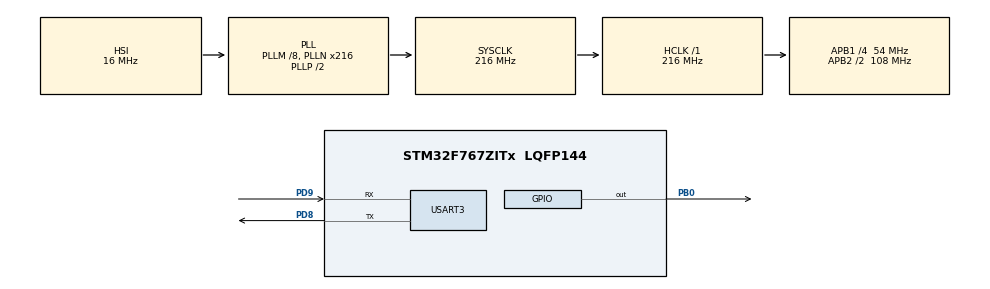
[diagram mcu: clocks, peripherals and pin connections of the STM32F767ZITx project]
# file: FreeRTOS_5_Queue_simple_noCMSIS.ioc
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FREERTOS.INCLUDE_vTaskDelayUntil=1
FREERTOS.Tasks01=normalTask,0,128,start_normalTask,Default,NULL,Dynamic,NULL,NULL
FREERTOS.configUSE_COUNTING_SEMAPHORES=0
FREERTOS.configUSE_NEWLIB_REENTRANT=1
Mcu.Family=STM32F7
Mcu.Name=STM32F767ZITx
Mcu.Package=LQFP144
NVIC.PriorityGroup=NVIC_PRIORITYGROUP_4
NVIC.TIM6_DAC_IRQn=true\:15\:0\:false\:false\:true\:false\:false\:true\:true
NVIC.TimeBase=TIM6_DAC_IRQn
NVIC.TimeBaseIP=TIM6
NVIC.USART3_IRQn=true\:5\:0\:false\:false\:true\:true\:true\:true\:true
PA13.Mode=Serial_Wire
PA13.Signal=SYS_JTMS-SWDIO
PA14.Mode=Serial_Wire
PA14.Signal=SYS_JTCK-SWCLK
PB0.Signal=GPIO_Output
PD8.Mode=Asynchronous
PD8.Signal=USART3_TX
PD9.Mode=Asynchronous
PD9.Signal=USART3_RX
ProjectManager.HeapSize=0x200
ProjectManager.StackSize=0x400
ProjectManager.TargetToolchain=CMake
RCC.AHBFreq_Value=216000000
RCC.APB1CLKDivider=RCC_HCLK_DIV4
RCC.APB1Freq_Value=54000000
RCC.APB1TimFreq_Value=108000000
RCC.APB2CLKDivider=RCC_HCLK_DIV2
RCC.APB2Freq_Value=108000000
RCC.APB2TimFreq_Value=216000000
RCC.CortexFreq_Value=216000000
RCC.HCLKFreq_Value=216000000
RCC.HSE_VALUE=8000000
RCC.HSI_VALUE=16000000
RCC.LSE_VALUE=32768
RCC.PLLM=8
RCC.PLLN=216
RCC.SYSCLKFreq_VALUE=216000000
RCC.SYSCLKSource=RCC_SYSCLKSOURCE_PLLCLK
RCC.USBFreq_Value=216000000
RCC.VCOOutputFreq_Value=432000000
USART3.VirtualMode-Asynchronous=VM_ASYNC
VP_FREERTOS_VS_CMSIS_V1.Mode=CMSIS_V1
VP_SYS_VS_tim6.Mode=TIM6
board=custom

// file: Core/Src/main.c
/* USER CODE BEGIN Header */
/**
  ******************************************************************************
  * @file           : main.c
  * @brief          : Main program body
  ******************************************************************************
  * @author			: Jabed-Akhtar (GitHub)
  * @date			: 11.10.2022
  ******************************************************************************
  * Description:
  * 	- a source within this script: https://youtube.com/playlist?list=PLfIJKC1ud8gj1t2y36sabPT4YcKzmN_5D
  * 	- Related doc/file can be found at location '<project-dir>/zz_docs/FreeRTOS_5_Queue_simple_noCMSIS_161204_Mastering_the_FreeRTOS_Real_Time_Kernel-A_Hands-On_Tutorial_Guide-Page-131.jpg'
  * 	- Task Sender_HPT_Task sends data every 2 sec
  * 	- Task Sender_LPT_Task sends data every 1 sec
  * 	- Task Receiver_Task reads data from Queue every 5 sec
  * 	- Rx_UART write data to front of Queue (when the Queue is full, data
  * 	  won't be written to Queue -> to test, write data in the beginning
  * 	  of programm execution.)
  *
  * @attention
  * Very imp note:
  * 	- comment out #include "cmsis_os.h" , as it is not used
  * 	- comment or remote by-default created task related stuffs
  *
  ******************************************************************************
  */
/* USER CODE END Header */
#include "main.h"
//#include "cmsis_os.h"

/* USER CODE BEGIN Includes */

#include "FreeRTOS.h"
#include "task.h"
#include "timers.h"
#include "queue.h"
#include "semphr.h"
#include "event_groups.h"

#include <stdio.h>
#include "stdlib.h"
#include <string.h>

/* USER CODE END Includes */

UART_HandleTypeDef huart3;

//osThreadId normalTaskHandle;
/* USER CODE BEGIN PV */

// defining Task Handlers
xTaskHandle Sender_HPT_Handler;
xTaskHandle Sender_LPT_Handler;
xTaskHandle Receiver_Handler;

// defining Queue Handlers
xQueueHandle simpleQueue;

uint8_t Rx_data;

/* USER CODE END PV */

void SystemClock_Config(void);
static void MX_GPIO_Init(void);
static void MX_USART3_UART_Init(void);
//void start_normalTask(void const * argument);

/* USER CODE BEGIN PFP */

void Sender_HPT_Task(void *argument); // Sender High Priority task Handler function
void Sender_LPT_Task(void *argument); // Sender Low Priority task Handler function
void Receiver_Task(void *argument); // Receiver task Handler function

/* USER CODE END PFP */

int main(void)
{

  /* MCU Configuration--------------------------------------------------------*/

  /* Reset of all peripherals, Initializes the Flash interface and the Systick. */
  HAL_Init();

  /* Configure the system clock */
  SystemClock_Config();

  /* Initialize all configured peripherals */
  MX_GPIO_Init();
  MX_USART3_UART_Init();
  /* USER CODE BEGIN 2 */

  // sending data through USART at the beginning of Programm
  char stri[] = "\n---------- Programm started!!! ----------\n\n\r";
  HAL_UART_Transmit(&huart3, (uint8_t*)stri, strlen(stri), HAL_MAX_DELAY); //HAL_MAX_DELAY -> 0xFFFFFFFFU

  // creating Queue **********
  simpleQueue = xQueueCreate(5, sizeof(int));
  if (simpleQueue == 0) // if Queue not created
  {
	  char *str1 = "Unable to create Queue.\n\r";
	  HAL_UART_Transmit(&huart3, (uint8_t*)str1, strlen(str1), HAL_MAX_DELAY);
  }
  else
  {
	  char *str1 = "Integer Queue successfully created.\n\r";
	  HAL_UART_Transmit(&huart3, (uint8_t*)str1, strlen(str1), HAL_MAX_DELAY);
  }

  // create Tasks **********
  xTaskCreate(Sender_HPT_Task, "Sender_HPT", 128, NULL, 3, &Sender_HPT_Handler); // -> High Priority Task
  xTaskCreate(Sender_LPT_Task, "Sender_LPT", 128, (void *)111, 2, &Sender_LPT_Handler); // -> Low Priority Task
  xTaskCreate(Receiver_Task, "Receive", 128, NULL, 1, &Receiver_Handler); // Task for receiving data from Queue

  HAL_UART_Receive_IT(&huart3, &Rx_data, 1);

  vTaskStartScheduler();

  /* USER CODE END 2 */

  /* Create the thread(s) */
  /* definition and creation of normalTask */
//  osThreadDef(normalTask, start_normalTask, osPriorityNormal, 0, 128);
//  normalTaskHandle = osThreadCreate(osThread(normalTask), NULL);

  /* Start scheduler */
//  osKernelStart();

  /* We should never get here as control is now taken by the scheduler */

  /* Infinite loop */
  while (1)
  {

  }
}

void SystemClock_Config(void)
{
  RCC_OscInitTypeDef RCC_OscInitStruct = {0};
  RCC_ClkInitTypeDef RCC_ClkInitStruct = {0};

  /** Configure the main internal regulator output voltage
  */
  __HAL_RCC_PWR_CLK_ENABLE();
  __HAL_PWR_VOLTAGESCALING_CONFIG(PWR_REGULATOR_VOLTAGE_SCALE1);

  /** Initializes the RCC Oscillators according to the specified parameters
  * in the RCC_OscInitTypeDef structure.
  */
  RCC_OscInitStruct.OscillatorType = RCC_OSCILLATORTYPE_HSI;
  RCC_OscInitStruct.HSIState = RCC_HSI_ON;
  RCC_OscInitStruct.HSICalibrationValue = RCC_HSICALIBRATION_DEFAULT;
  RCC_OscInitStruct.PLL.PLLState = RCC_PLL_ON;
  RCC_OscInitStruct.PLL.PLLSource = RCC_PLLSOURCE_HSI;
  RCC_OscInitStruct.PLL.PLLM = 8;
  RCC_OscInitStruct.PLL.PLLN = 216;
  RCC_OscInitStruct.PLL.PLLP = RCC_PLLP_DIV2;
  RCC_OscInitStruct.PLL.PLLQ = 2;
  RCC_OscInitStruct.PLL.PLLR = 2;
  if (HAL_RCC_OscConfig(&RCC_OscInitStruct) != HAL_OK)
  {
    Error_Handler();
  }

  /** Activate the Over-Drive mode
  */
  if (HAL_PWREx_EnableOverDrive() != HAL_OK)
  {
    Error_Handler();
  }

  /** Initializes the CPU, AHB and APB buses clocks
  */
  RCC_ClkInitStruct.ClockType = RCC_CLOCKTYPE_HCLK|RCC_CLOCKTYPE_SYSCLK
                              |RCC_CLOCKTYPE_PCLK1|RCC_CLOCKTYPE_PCLK2;
  RCC_ClkInitStruct.SYSCLKSource = RCC_SYSCLKSOURCE_PLLCLK;
  RCC_ClkInitStruct.AHBCLKDivider = RCC_SYSCLK_DIV1;
  RCC_ClkInitStruct.APB1CLKDivider = RCC_HCLK_DIV4;
  RCC_ClkInitStruct.APB2CLKDivider = RCC_HCLK_DIV2;

  if (HAL_RCC_ClockConfig(&RCC_ClkInitStruct, FLASH_LATENCY_7) != HAL_OK)
  {
    Error_Handler();
  }
}

static void MX_USART3_UART_Init(void)
{

  huart3.Instance = USART3;
  huart3.Init.BaudRate = 115200;
  huart3.Init.WordLength = UART_WORDLENGTH_8B;
  huart3.Init.StopBits = UART_STOPBITS_1;
  huart3.Init.Parity = UART_PARITY_NONE;
  huart3.Init.Mode = UART_MODE_TX_RX;
  huart3.Init.HwFlowCtl = UART_HWCONTROL_NONE;
  huart3.Init.OverSampling = UART_OVERSAMPLING_16;
  huart3.Init.OneBitSampling = UART_ONE_BIT_SAMPLE_DISABLE;
  huart3.AdvancedInit.AdvFeatureInit = UART_ADVFEATURE_NO_INIT;
  if (HAL_UART_Init(&huart3) != HAL_OK)
  {
    Error_Handler();
  }

}

static void MX_GPIO_Init(void)
{
  GPIO_InitTypeDef GPIO_InitStruct = {0};

  /* GPIO Ports Clock Enable */
  __HAL_RCC_GPIOB_CLK_ENABLE();
  __HAL_RCC_GPIOD_CLK_ENABLE();
  __HAL_RCC_GPIOA_CLK_ENABLE();

  /*Configure GPIO pin Output Level */
  HAL_GPIO_WritePin(GPIOB, GPIO_PIN_0, GPIO_PIN_RESET);

  /*Configure GPIO pin : PB0 */
  GPIO_InitStruct.Pin = GPIO_PIN_0;
  GPIO_InitStruct.Mode = GPIO_MODE_OUTPUT_PP;
  GPIO_InitStruct.Pull = GPIO_NOPULL;
  GPIO_InitStruct.Speed = GPIO_SPEED_FREQ_LOW;
  HAL_GPIO_Init(GPIOB, &GPIO_InitStruct);

}

/* USER CODE BEGIN 4 */

// Sender High Priority task Handler function
/*
 * High Priority Task for sending Data to Queue
 */
void Sender_HPT_Task(void *argument)
{
	int i=222; // data to send to Queue
	uint32_t tickDelay = pdMS_TO_TICKS(2000);
	while(1)
	{
		char *str1 = "\n\nEntered Sender_HPT_Task.\n\rAbout to Send a number To the Queue.\n\r";
		HAL_UART_Transmit(&huart3, (uint8_t*)str1, strlen(str1), HAL_MAX_DELAY);

		// Sending Data to Queue when token is available
		if(xQueueSend(simpleQueue, &i, portMAX_DELAY) == pdPASS)
		{
			char *str2 = "Successfully sent number to the Queue.\n\rLeaving Sender_HPT_Task.\n\n\r";
			HAL_UART_Transmit(&huart3, (uint8_t*)str2, strlen(str2), HAL_MAX_DELAY);
		}

		vTaskDelay(tickDelay); // delay/pause task for 2 sec
	}
}

// Sender Low Priority task Handler function
/*
 * Low Priority Task for sending Data to Queue
 */
void Sender_LPT_Task(void *argument)
{
	int toSend; // data to send to Queue (comes from function argument later)
	uint32_t tickDelay = pdMS_TO_TICKS(1000);
	while(1)
	{
		toSend = (int) argument;
		char *str1 = "Entered Sender_LPT_Task.\n\rAbout to Send a number To the Queue.\n\r";
		HAL_UART_Transmit(&huart3, (uint8_t*)str1, strlen(str1), HAL_MAX_DELAY);

		// Sending Data to Queue when token is available
		xQueueSend(simpleQueue, &toSend, portMAX_DELAY);

		char *str2 = "Successfully sent number to the Queue.\n\rLeaving Sender_LPT_Task.\n\n\r";
		HAL_UART_Transmit(&huart3, (uint8_t*)str2, strlen(str2), HAL_MAX_DELAY);

		vTaskDelay(tickDelay); // delay/pause task for 1 sec
	}
}

// Receiver task Handler function
/*
 * Receiver Task for receiving Data from Queue
 */
void Receiver_Task(void *argument)
{
	int received = 0;
	uint32_t tickDelay = pdMS_TO_TICKS(5000);
	while(1)
	{
		char str[100];
		strcpy(str, "Entered Receiver_Task.\n\rAbout to Receive a number From the Queue.\n\r");
		HAL_UART_Transmit(&huart3, (uint8_t*)str, strlen(str), HAL_MAX_DELAY);

		// Sending Data to Queue when token is available
		if(xQueueReceive(simpleQueue, &received, portMAX_DELAY) != pdTRUE)
		{
			HAL_UART_Transmit(&huart3, (uint8_t*)"Error in Receiving from Queue.\n\n\r", 32, 1000);
		}
		else
		{
			sprintf(str, "Successfully Received Number %d from the Queue.\n\rLeaving Receiver_Task.\n\n\r", received);
			HAL_UART_Transmit(&huart3, (uint8_t*)str, strlen(str), HAL_MAX_DELAY);
		}

		vTaskDelay(tickDelay); // delay/pause task for 5 sec
	}
}

// Callback function for UART_Rx_Interrupt
/*
 * Call back function to receive command through UART
 */
void HAL_UART_RxCpltCallback(UART_HandleTypeDef *huart)
{
	HAL_UART_Receive_IT(huart, &Rx_data, 1);
	int toSend = 1234567890;
	char str[100];
	if (Rx_data == 'r')
	{
		/*
		 * the xHigherPriorityTaskWoken parameter must be initialized to pdFALSE as
		 * it will get set to pdTRUE inside the interrupt safe API function if a context
		 * switch is required.
		 */
		BaseType_t xHigherPriorityTaskWoken = pdFALSE;

		// Sending Data to Queue when token is available
		if(xQueueSendToFrontFromISR(simpleQueue, &toSend, &xHigherPriorityTaskWoken) == pdPASS)
		{
			HAL_GPIO_TogglePin(GPIOB, GPIO_PIN_0); // Blink LED when Data is sent successfully
			sprintf(str, "Number %d Sent from ISR to Queue.\n\n", toSend);
			HAL_UART_Transmit(&huart3, (uint8_t*)str, strlen(str), HAL_MAX_DELAY);
		}

		/*
		 * Pass the xHigherPriorityTaskWoken value into portEND_SWITCHING_ISR(). If
		 * xHigherPriorityTaskWoken was set to pdTRUE inside xSemaphoreGiveFromISR()
		 * xHigherPriorityTaskWoken is still pdFALSE then calling portEND_SWITCHING_ISR()
		 * will have no effect.
		 */
		portEND_SWITCHING_ISR(xHigherPriorityTaskWoken); // {}-> needed to write this in every ISR function
	}
}

/* USER CODE END 4 */

//void start_normalTask(void const * argument)
//{
//  /* USER CODE BEGIN 5 */
//  /* Infinite loop */
//  for(;;)
//  {
//    osDelay(1);
//  }
//  /* USER CODE END 5 */
//}

void HAL_TIM_PeriodElapsedCallback(TIM_HandleTypeDef *htim)
{
  if (htim->Instance == TIM6) {
    HAL_IncTick();
  }
}

void Error_Handler(void)
{
  __disable_irq();
  while (1)
  {
  }
}
